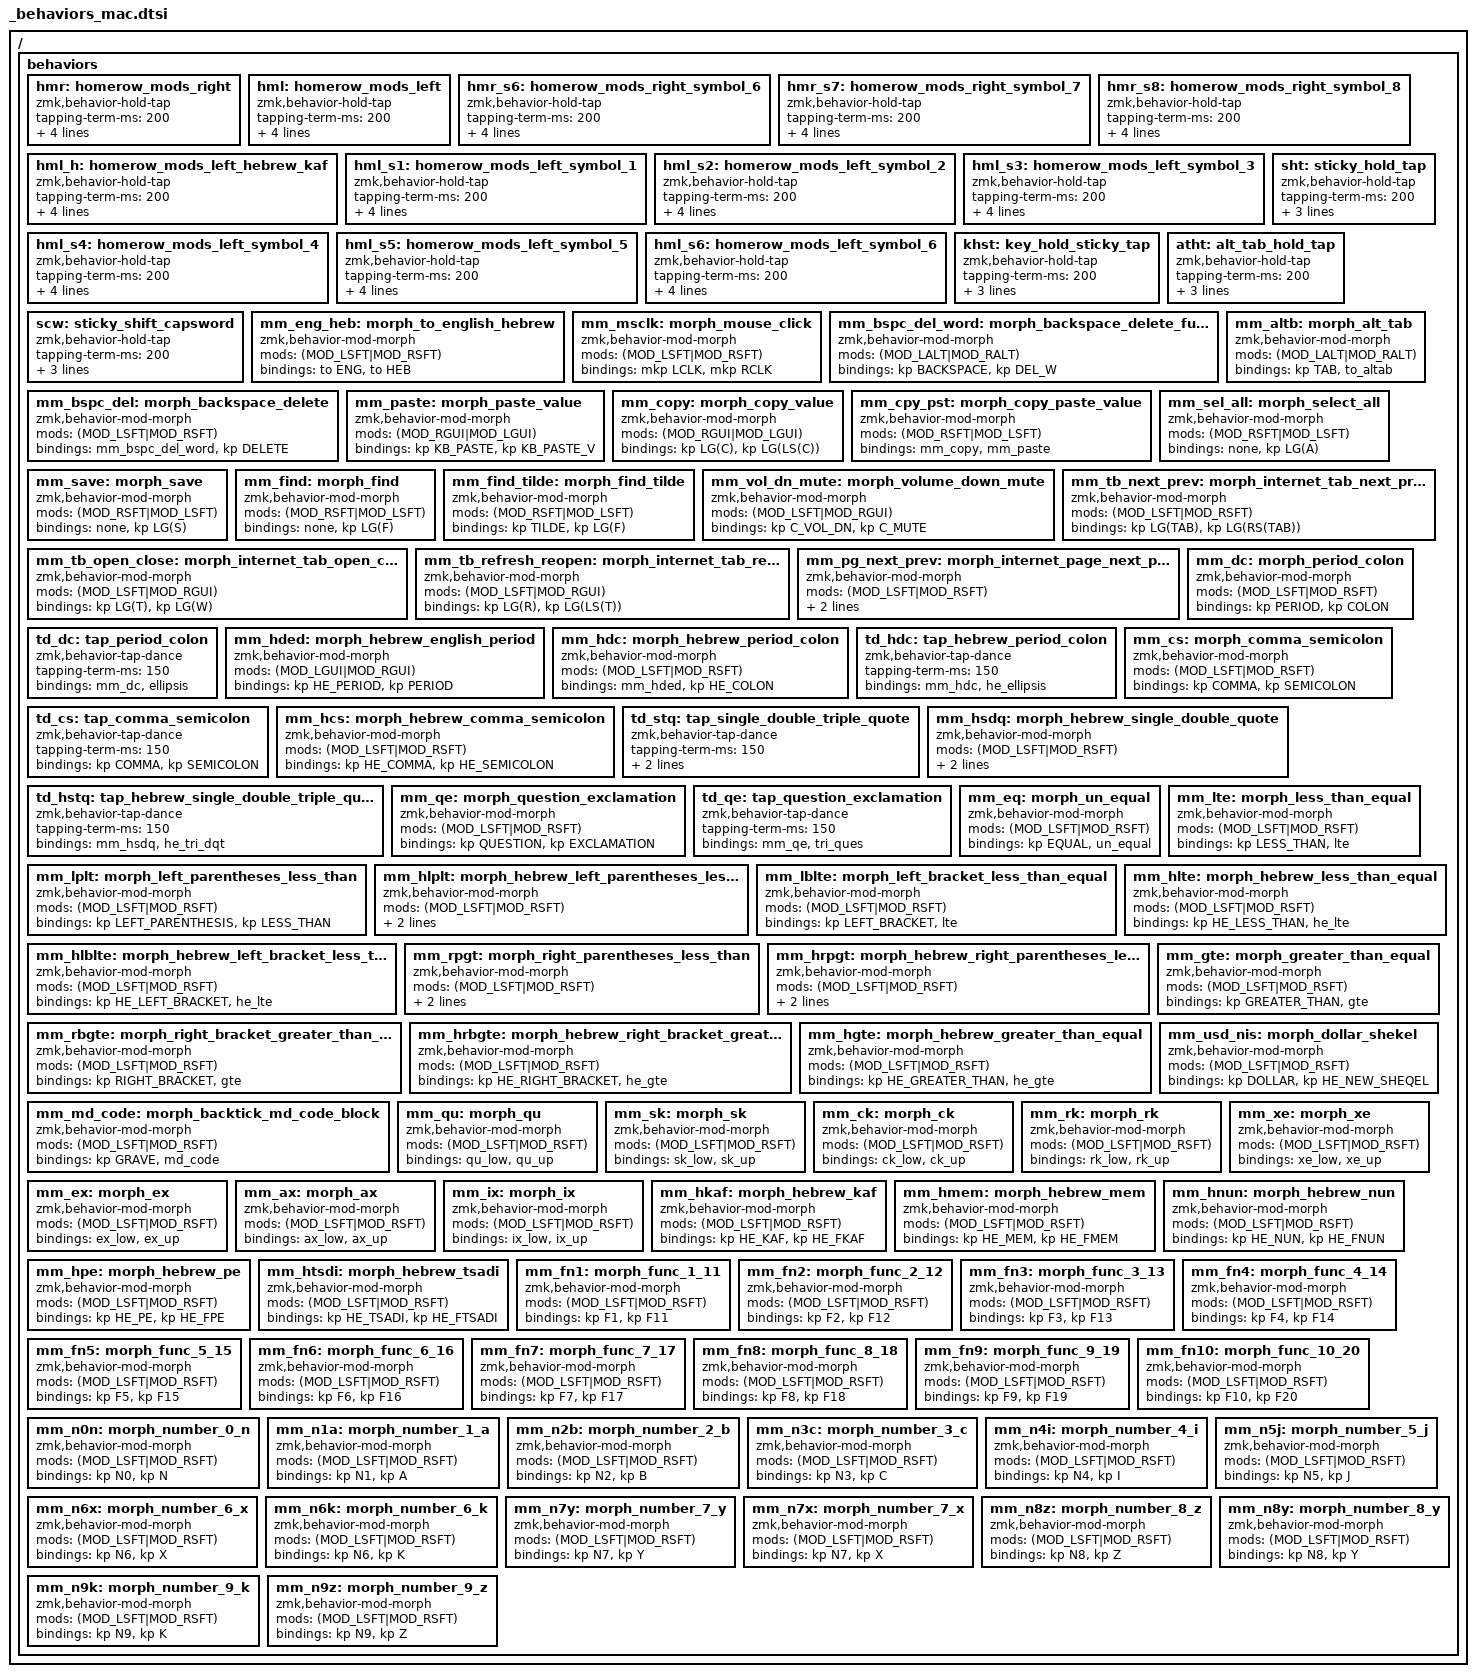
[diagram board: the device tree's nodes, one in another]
/ {
    behaviors {
        hmr: homerow_mods_right {
            compatible = "zmk,behavior-hold-tap";
            #binding-cells = <2>;
            tapping-term-ms = <200>;
            quick_tap_ms = <0>;
            flavor = "tap-preferred";
            bindings = <&kp>, <&kp>;
            hold-trigger-key-positions = <KEYS_L>;
        };

        hml: homerow_mods_left {
            compatible = "zmk,behavior-hold-tap";
            #binding-cells = <2>;
            tapping-term-ms = <200>;
            quick_tap_ms = <0>;
            flavor = "tap-preferred";
            bindings = <&kp>, <&kp>;
            hold-trigger-key-positions = <KEYS_R>;
        };

        hmr_s6: homerow_mods_right_symbol_6 {
            compatible = "zmk,behavior-hold-tap";
            #binding-cells = <2>;
            tapping-term-ms = <200>;
            quick_tap_ms = <0>;
            flavor = "tap-preferred";
            bindings = <&kp>, <&mm_n6x>;
            hold-trigger-key-positions = <KEYS_L>;
        };

        hmr_s7: homerow_mods_right_symbol_7 {
            compatible = "zmk,behavior-hold-tap";
            #binding-cells = <2>;
            tapping-term-ms = <200>;
            quick_tap_ms = <0>;
            flavor = "tap-preferred";
            bindings = <&kp>, <&mm_n7y>;
            hold-trigger-key-positions = <KEYS_L>;
        };

        hmr_s8: homerow_mods_right_symbol_8 {
            compatible = "zmk,behavior-hold-tap";
            #binding-cells = <2>;
            tapping-term-ms = <200>;
            quick_tap_ms = <0>;
            flavor = "tap-preferred";
            bindings = <&kp>, <&mm_n8z>;
            hold-trigger-key-positions = <KEYS_L>;
        };

        hml_h: homerow_mods_left_hebrew_kaf {
            compatible = "zmk,behavior-hold-tap";
            #binding-cells = <2>;
            tapping-term-ms = <200>;
            quick_tap_ms = <0>;
            flavor = "tap-preferred";
            bindings = <&kp>, <&mm_hkaf>;
            hold-trigger-key-positions = <KEYS_R>;
        };

        hml_s1: homerow_mods_left_symbol_1 {
            compatible = "zmk,behavior-hold-tap";
            #binding-cells = <2>;
            tapping-term-ms = <200>;
            quick_tap_ms = <0>;
            flavor = "tap-preferred";
            bindings = <&kp>, <&mm_n1a>;
            hold-trigger-key-positions = <KEYS_R>;
        };

        hml_s2: homerow_mods_left_symbol_2 {
            compatible = "zmk,behavior-hold-tap";
            #binding-cells = <2>;
            tapping-term-ms = <200>;
            quick_tap_ms = <0>;
            flavor = "tap-preferred";
            bindings = <&kp>, <&mm_n2b>;
            hold-trigger-key-positions = <KEYS_R>;
        };

        hml_s3: homerow_mods_left_symbol_3 {
            compatible = "zmk,behavior-hold-tap";
            #binding-cells = <2>;
            tapping-term-ms = <200>;
            quick_tap_ms = <0>;
            flavor = "tap-preferred";
            bindings = <&kp>, <&mm_n3c>;
            hold-trigger-key-positions = <KEYS_R>;
        };

        hml_s4: homerow_mods_left_symbol_4 {
            compatible = "zmk,behavior-hold-tap";
            #binding-cells = <2>;
            tapping-term-ms = <200>;
            quick_tap_ms = <0>;
            flavor = "tap-preferred";
            bindings = <&kp>, <&mm_n4i>;
            hold-trigger-key-positions = <KEYS_R>;
        };

        hml_s5: homerow_mods_left_symbol_5 {
            compatible = "zmk,behavior-hold-tap";
            #binding-cells = <2>;
            tapping-term-ms = <200>;
            quick_tap_ms = <0>;
            flavor = "tap-preferred";
            bindings = <&kp>, <&mm_n5j>;
            hold-trigger-key-positions = <KEYS_R>;
        };

        hml_s6: homerow_mods_left_symbol_6 {
            compatible = "zmk,behavior-hold-tap";
            #binding-cells = <2>;
            tapping-term-ms = <200>;
            quick_tap_ms = <0>;
            flavor = "tap-preferred";
            bindings = <&kp>, <&mm_n6k>;
            hold-trigger-key-positions = <KEYS_R>;
        };

        sht: sticky_hold_tap {
            compatible = "zmk,behavior-hold-tap";
            #binding-cells = <2>;
            tapping-term-ms = <200>;
            quick_tap_ms = <0>;
            flavor = "tap-preferred";
            bindings = <&sk>, <&kp>;
        };

        khst: key_hold_sticky_tap {
            compatible = "zmk,behavior-hold-tap";
            #binding-cells = <2>;
            tapping-term-ms = <200>;
            quick_tap_ms = <0>;
            flavor = "tap-preferred";
            bindings = <&kp>, <&sk>;
        };

        atht: alt_tab_hold_tap {
            compatible = "zmk,behavior-hold-tap";
            #binding-cells = <2>;
            tapping-term-ms = <200>;
            quick_tap_ms = <0>;
            flavor = "tap-preferred";
            bindings = <&to_altab>, <&kp>;
        };

        scw: sticky_shift_capsword {
            compatible = "zmk,behavior-hold-tap";
            #binding-cells = <2>;
            tapping-term-ms = <200>;
            quick_tap_ms = <0>;
            flavor = "tap-preferred";
            bindings = <&caps_word>, <&sk>;
        };

        // LAYER
        // To ENGLISH; Shifted: To Hebrew

        mm_eng_heb: morph_to_english_hebrew {
            compatible = "zmk,behavior-mod-morph";
            #binding-cells = <0>;
            mods = <(MOD_LSFT|MOD_RSFT)>;
            bindings = <&to ENG>, <&to HEB>;
        };

        // To KEYBOARD; Shifted: To MOUSE
        // To SYMBOL; Shifted: To KEYBOARD

        // mm_sys_fn: morph_to_system_function {
        //     compatible = "zmk,behavior-mod-morph";
        //     #binding-cells = <0>;
        //     mods = <(MOD_LSFT|MOD_RSFT)>;
        //     bindings = <&to SYS>, <&to FUN>;
        // };

        // To SYMBOL; Shifted: To MOUSE
        // MOD MORPHS
        // GENERAL

        mm_msclk: morph_mouse_click {
            compatible = "zmk,behavior-mod-morph";
            #binding-cells = <0>;
            mods = <(MOD_LSFT|MOD_RSFT)>;
            bindings = <&mkp LCLK>, <&mkp RCLK>;
        };

        mm_bspc_del_word: morph_backspace_delete_full_word {
            compatible = "zmk,behavior-mod-morph";
            #binding-cells = <0>;
            mods = <(MOD_LALT|MOD_RALT)>;
            bindings = <&kp BACKSPACE>, <&kp DEL_W>;
        };

        mm_bspc_del: morph_backspace_delete {
            compatible = "zmk,behavior-mod-morph";
            #binding-cells = <0>;
            mods = <(MOD_LSFT|MOD_RSFT)>;
            bindings = <&mm_bspc_del_word>, <&kp DELETE>;
        };

        mm_altb: morph_alt_tab {
            compatible = "zmk,behavior-mod-morph";
            #binding-cells = <0>;
            mods = <(MOD_LALT|MOD_RALT)>;
            bindings = <&kp TAB>, <&to_altab>;
        };

        // mm_paste: morph_paste_value {
        //     compatible = "zmk,behavior-mod-morph";
        //     #binding-cells = <0>;
        //     mods = <(MOD_RGUI|MOD_LGUI)>;
        //     bindings = <&kp LG(V)>, <&kp LG(LS(V))>;
        // };

        mm_paste: morph_paste_value {
            compatible = "zmk,behavior-mod-morph";
            #binding-cells = <0>;
            mods = <(MOD_RGUI|MOD_LGUI)>;
            bindings = <&kp KB_PASTE>, <&kp KB_PASTE_V>;
        };

        mm_copy: morph_copy_value {
            compatible = "zmk,behavior-mod-morph";
            #binding-cells = <0>;
            mods = <(MOD_RGUI|MOD_LGUI)>;
            bindings = <&kp LG(C)>, <&kp LG(LS(C))>;
        };

        mm_cpy_pst: morph_copy_paste_value {
            compatible = "zmk,behavior-mod-morph";
            #binding-cells = <0>;
            mods = <(MOD_RSFT|MOD_LSFT)>;
            bindings = <&mm_copy>, <&mm_paste>;
        };

        // mm_cpy_pst: morph_copy_paste {
        //     compatible = "zmk,behavior-mod-morph";
        //     #binding-cells = <0>;
        //     mods = <(MOD_RGUI|MOD_LGUI)>;
        //     bindings = <&kp LG(C)>, <&kp LG(V)>;
        // };

        mm_sel_all: morph_select_all {
            compatible = "zmk,behavior-mod-morph";
            #binding-cells = <0>;
            mods = <(MOD_RSFT|MOD_LSFT)>;
            bindings = <&none>, <&kp LG(A)>;
        };


        mm_save: morph_save {
            compatible = "zmk,behavior-mod-morph";
            #binding-cells = <0>;
            mods = <(MOD_RSFT|MOD_LSFT)>;
            bindings = <&none>, <&kp LG(S)>;
        };

        mm_find: morph_find {
            compatible = "zmk,behavior-mod-morph";
            #binding-cells = <0>;
            mods = <(MOD_RSFT|MOD_LSFT)>;
            bindings = <&none>, <&kp LG(F)>;
        };

        mm_find_tilde: morph_find_tilde {
            compatible = "zmk,behavior-mod-morph";
            #binding-cells = <0>;
            mods = <(MOD_RSFT|MOD_LSFT)>;
            bindings = <&kp TILDE>, <&kp LG(F)>;
        };

        mm_vol_dn_mute: morph_volume_down_mute {
            compatible = "zmk,behavior-mod-morph";
            #binding-cells = <0>;
            mods = <(MOD_LSFT|MOD_RGUI)>;
            bindings = <&kp C_VOL_DN>, <&kp C_MUTE>;
        };

        // INTERNET SHORTCUTS

        mm_tb_next_prev: morph_internet_tab_next_prev {
            compatible = "zmk,behavior-mod-morph";
            #binding-cells = <0>;
            mods = <(MOD_LSFT|MOD_RSFT)>;
            bindings = <&kp LG(TAB)>, <&kp LG(RS(TAB))>;
        };

        mm_tb_open_close: morph_internet_tab_open_close {
            compatible = "zmk,behavior-mod-morph";
            #binding-cells = <0>;
            mods = <(MOD_LSFT|MOD_RGUI)>;
            bindings = <&kp LG(T)>, <&kp LG(W)>;
        };

        mm_tb_refresh_reopen: morph_internet_tab_refresh_reop {
            compatible = "zmk,behavior-mod-morph";
            #binding-cells = <0>;
            mods = <(MOD_LSFT|MOD_RGUI)>;
            bindings = <&kp LG(R)>, <&kp LG(LS(T))>;
        };

        mm_pg_next_prev: morph_internet_page_next_prev {
            compatible = "zmk,behavior-mod-morph";
            #binding-cells = <0>;
            mods = <(MOD_LSFT|MOD_RSFT)>;
            bindings = <&kp LA(RIGHT_ARROW)>, <&kp LA(LEFT_ARROW)>;
        };

        // PUNCTUATION
        // Mod-Morph: Period "."; Colon ":"

        mm_dc: morph_period_colon {
            compatible = "zmk,behavior-mod-morph";
            #binding-cells = <0>;
            mods = <(MOD_LSFT|MOD_RSFT)>;
            bindings = <&kp PERIOD>, <&kp COLON>;
        };

        // Tap-Dance: 1) Mod-Morph Period-Colon; 2) Ellipsis "..."

        td_dc: tap_period_colon {
            compatible = "zmk,behavior-tap-dance";
            #binding-cells = <0>;
            tapping-term-ms = <150>;
            bindings = <&mm_dc>, <&ellipsis>;
        };

        // Mod-Morph: Period "."; Colon ":"

        mm_hded: morph_hebrew_english_period {
            compatible = "zmk,behavior-mod-morph";
            #binding-cells = <0>;
            mods = <(MOD_LGUI|MOD_RGUI)>;
            bindings = <&kp HE_PERIOD>, <&kp PERIOD>;
        };

        // Mod-Morph: Period "."; Colon ":"

        mm_hdc: morph_hebrew_period_colon {
            compatible = "zmk,behavior-mod-morph";
            #binding-cells = <0>;
            mods = <(MOD_LSFT|MOD_RSFT)>;
            bindings = <&mm_hded>, <&kp HE_COLON>;
        };

        // 1) Mod-Morph Period-Colon; 2) Ellipsis "..."

        td_hdc: tap_hebrew_period_colon {
            compatible = "zmk,behavior-tap-dance";
            #binding-cells = <0>;
            tapping-term-ms = <150>;
            bindings = <&mm_hdc>, <&he_ellipsis>;
        };

        // Mod-Morph: Comma ","; Semicolon ";"

        mm_cs: morph_comma_semicolon {
            compatible = "zmk,behavior-mod-morph";
            #binding-cells = <0>;
            mods = <(MOD_LSFT|MOD_RSFT)>;
            bindings = <&kp COMMA>, <&kp SEMICOLON>;
        };

        // Tap-Dance: 1) Comma ","; 2) Semicolon ";"

        td_cs: tap_comma_semicolon {
            compatible = "zmk,behavior-tap-dance";
            #binding-cells = <0>;
            tapping-term-ms = <150>;
            bindings = <&kp COMMA>, <&kp SEMICOLON>;
        };

        // Mod-Morph: Comma ","; Semicolon ";"

        mm_hcs: morph_hebrew_comma_semicolon {
            compatible = "zmk,behavior-mod-morph";
            #binding-cells = <0>;
            mods = <(MOD_LSFT|MOD_RSFT)>;
            bindings = <&kp HE_COMMA>, <&kp HE_SEMICOLON>;
        };

        // 1: Single quote "'"; 2: Double quote """; 3: Triple-double quote """""

        td_stq: tap_single_double_triple_quote {
            compatible = "zmk,behavior-tap-dance";
            #binding-cells = <0>;
            tapping-term-ms = <150>;
            bindings = <&kp SINGLE_QUOTE>, <&kp DOUBLE_QUOTES>, <&tri_dqt>;
        };

        // Mod-Morph: Single Quote "'"; Double Quote """

        mm_hsdq: morph_hebrew_single_double_quote {
            compatible = "zmk,behavior-mod-morph";
            #binding-cells = <0>;
            mods = <(MOD_LSFT|MOD_RSFT)>;
            bindings = <&kp HE_SINGLE_QUOTE>, <&kp HE_DOUBLE_QUOTES>;
        };

        // Tap-Dance: 1) Mod-Morph Single-Double Quote; 2) Triple-Double Quote """""

        td_hstq: tap_hebrew_single_double_triple_quote {
            compatible = "zmk,behavior-tap-dance";
            #binding-cells = <0>;
            tapping-term-ms = <150>;
            bindings = <&mm_hsdq>, <&he_tri_dqt>;
        };

        // Mod-Morph: Question "?"; Exclamation "!"

        mm_qe: morph_question_exclamation {
            compatible = "zmk,behavior-mod-morph";
            #binding-cells = <0>;
            mods = <(MOD_LSFT|MOD_RSFT)>;
            bindings = <&kp QUESTION>, <&kp EXCLAMATION>;
        };

        // Tap-Dance: 1) Mod-Morph Question-Exclamation; 2) Triple Question "???"

        td_qe: tap_question_exclamation {
            compatible = "zmk,behavior-tap-dance";
            #binding-cells = <0>;
            tapping-term-ms = <150>;
            bindings = <&mm_qe>, <&tri_ques>;
        };

        // MATH OPERATORS

        mm_eq: morph_un_equal {
            compatible = "zmk,behavior-mod-morph";
            #binding-cells = <0>;
            mods = <(MOD_LSFT|MOD_RSFT)>;
            bindings = <&kp EQUAL>, <&un_equal>;
        };

        mm_lplt: morph_left_parentheses_less_than {
            compatible = "zmk,behavior-mod-morph";
            #binding-cells = <0>;
            mods = <(MOD_LSFT|MOD_RSFT)>;
            bindings = <&kp LEFT_PARENTHESIS>, <&kp LESS_THAN>;
        };

        mm_hlplt: morph_hebrew_left_parentheses_less_than {
            compatible = "zmk,behavior-mod-morph";
            #binding-cells = <0>;
            mods = <(MOD_LSFT|MOD_RSFT)>;
            bindings = <&kp HE_LEFT_PARENTHESIS>, <&kp HE_LESS_THAN>;
        };

        mm_lblte: morph_left_bracket_less_than_equal {
            compatible = "zmk,behavior-mod-morph";
            #binding-cells = <0>;
            mods = <(MOD_LSFT|MOD_RSFT)>;
            bindings = <&kp LEFT_BRACKET>, <&lte>;
        };

        mm_hlblte: morph_hebrew_left_bracket_less_than_equal {
            compatible = "zmk,behavior-mod-morph";
            #binding-cells = <0>;
            mods = <(MOD_LSFT|MOD_RSFT)>;
            bindings = <&kp HE_LEFT_BRACKET>, <&he_lte>;
        };

        mm_lte: morph_less_than_equal {
            compatible = "zmk,behavior-mod-morph";
            #binding-cells = <0>;
            mods = <(MOD_LSFT|MOD_RSFT)>;
            bindings = <&kp LESS_THAN>, <&lte>;
        };

        mm_hlte: morph_hebrew_less_than_equal {
            compatible = "zmk,behavior-mod-morph";
            #binding-cells = <0>;
            mods = <(MOD_LSFT|MOD_RSFT)>;
            bindings = <&kp HE_LESS_THAN>, <&he_lte>;
        };

        mm_rpgt: morph_right_parentheses_less_than {
            compatible = "zmk,behavior-mod-morph";
            #binding-cells = <0>;
            mods = <(MOD_LSFT|MOD_RSFT)>;
            bindings = <&kp RIGHT_PARENTHESIS>, <&kp GREATER_THAN>;
        };

        mm_hrpgt: morph_hebrew_right_parentheses_less_than {
            compatible = "zmk,behavior-mod-morph";
            #binding-cells = <0>;
            mods = <(MOD_LSFT|MOD_RSFT)>;
            bindings = <&kp HE_RIGHT_PARENTHESIS>, <&kp HE_GREATER_THAN>;
        };

        mm_rbgte: morph_right_bracket_greater_than_equal {
            compatible = "zmk,behavior-mod-morph";
            #binding-cells = <0>;
            mods = <(MOD_LSFT|MOD_RSFT)>;
            bindings = <&kp RIGHT_BRACKET>, <&gte>;
        };

        mm_hrbgte: morph_hebrew_right_bracket_greater_than_equal {
            compatible = "zmk,behavior-mod-morph";
            #binding-cells = <0>;
            mods = <(MOD_LSFT|MOD_RSFT)>;
            bindings = <&kp HE_RIGHT_BRACKET>, <&he_gte>;
        };

        mm_gte: morph_greater_than_equal {
            compatible = "zmk,behavior-mod-morph";
            #binding-cells = <0>;
            mods = <(MOD_LSFT|MOD_RSFT)>;
            bindings = <&kp GREATER_THAN>, <&gte>;
        };

        mm_hgte: morph_hebrew_greater_than_equal {
            compatible = "zmk,behavior-mod-morph";
            #binding-cells = <0>;
            mods = <(MOD_LSFT|MOD_RSFT)>;
            bindings = <&kp HE_GREATER_THAN>, <&he_gte>;
        };

        mm_md_code: morph_backtick_md_code_block {
            compatible = "zmk,behavior-mod-morph";
            #binding-cells = <0>;
            mods = <(MOD_LSFT|MOD_RSFT)>;
            bindings = <&kp GRAVE>, <&md_code>;
        };

        // CHARACTERS
        // Mod-Morph: $; ₪
        mm_usd_nis: morph_dollar_shekel {
            compatible = "zmk,behavior-mod-morph";
            #binding-cells = <0>;
            mods = <(MOD_LSFT|MOD_RSFT)>;
            bindings = <&kp DOLLAR>, <&kp HE_NEW_SHEQEL>;
        };

        // LETTERS
        // Mod-Morph: qu; Qu

        mm_qu: morph_qu {
            compatible = "zmk,behavior-mod-morph";
            #binding-cells = <0>;
            mods = <(MOD_LSFT|MOD_RSFT)>;
            bindings = <&qu_low>, <&qu_up>;
        };

        // Mod-Morph: sk; Sk

        mm_sk: morph_sk {
            compatible = "zmk,behavior-mod-morph";
            #binding-cells = <0>;
            mods = <(MOD_LSFT|MOD_RSFT)>;
            bindings = <&sk_low>, <&sk_up>;
        };

        // Mod-Morph: ck; Ck

        mm_ck: morph_ck {
            compatible = "zmk,behavior-mod-morph";
            #binding-cells = <0>;
            mods = <(MOD_LSFT|MOD_RSFT)>;
            bindings = <&ck_low>, <&ck_up>;
        };

        // Mod-Morph: rk; Rk

        mm_rk: morph_rk {
            compatible = "zmk,behavior-mod-morph";
            #binding-cells = <0>;
            mods = <(MOD_LSFT|MOD_RSFT)>;
            bindings = <&rk_low>, <&rk_up>;
        };

        // Mod-Morph: xe; Xe

        mm_xe: morph_xe {
            compatible = "zmk,behavior-mod-morph";
            #binding-cells = <0>;
            mods = <(MOD_LSFT|MOD_RSFT)>;
            bindings = <&xe_low>, <&xe_up>;
        };

        // Mod-Morph: ex; Ex

        mm_ex: morph_ex {
            compatible = "zmk,behavior-mod-morph";
            #binding-cells = <0>;
            mods = <(MOD_LSFT|MOD_RSFT)>;
            bindings = <&ex_low>, <&ex_up>;
        };

        // Mod-Morph: ax; Ax

        mm_ax: morph_ax {
            compatible = "zmk,behavior-mod-morph";
            #binding-cells = <0>;
            mods = <(MOD_LSFT|MOD_RSFT)>;
            bindings = <&ax_low>, <&ax_up>;
        };

        // Mod-Morph: ix; Ix

        mm_ix: morph_ix {
            compatible = "zmk,behavior-mod-morph";
            #binding-cells = <0>;
            mods = <(MOD_LSFT|MOD_RSFT)>;
            bindings = <&ix_low>, <&ix_up>;
        };

        // Mod-Morph: Kaf כ; Final Kaf ך

        mm_hkaf: morph_hebrew_kaf {
            compatible = "zmk,behavior-mod-morph";
            #binding-cells = <0>;
            mods = <(MOD_LSFT|MOD_RSFT)>;
            bindings = <&kp HE_KAF>, <&kp HE_FKAF>;
        };

        // Mod-Morph: Mem מ; Final Mem ם

        mm_hmem: morph_hebrew_mem {
            compatible = "zmk,behavior-mod-morph";
            #binding-cells = <0>;
            mods = <(MOD_LSFT|MOD_RSFT)>;
            bindings = <&kp HE_MEM>, <&kp HE_FMEM>;
        };

        // Mod-Morph: Nun נ; Final Nun ן

        mm_hnun: morph_hebrew_nun {
            compatible = "zmk,behavior-mod-morph";
            #binding-cells = <0>;
            mods = <(MOD_LSFT|MOD_RSFT)>;
            bindings = <&kp HE_NUN>, <&kp HE_FNUN>;
        };

        // Mod-Morph: Peh פ; Final Peh ף

        mm_hpe: morph_hebrew_pe {
            compatible = "zmk,behavior-mod-morph";
            #binding-cells = <0>;
            mods = <(MOD_LSFT|MOD_RSFT)>;
            bindings = <&kp HE_PE>, <&kp HE_FPE>;
        };

        // Mod-Morph: Tsadi צ; Final Tsadi ץ

        mm_htsdi: morph_hebrew_tsadi {
            compatible = "zmk,behavior-mod-morph";
            #binding-cells = <0>;
            mods = <(MOD_LSFT|MOD_RSFT)>;
            bindings = <&kp HE_TSADI>, <&kp HE_FTSADI>;
        };

        // FUNCTION PLUS TEN

        mm_fn1: morph_func_1_11 {
            compatible = "zmk,behavior-mod-morph";
            #binding-cells = <0>;
            mods = <(MOD_LSFT|MOD_RSFT)>;
            bindings = <&kp F1>, <&kp F11>;
        };

        mm_fn2: morph_func_2_12 {
            compatible = "zmk,behavior-mod-morph";
            #binding-cells = <0>;
            mods = <(MOD_LSFT|MOD_RSFT)>;
            bindings = <&kp F2>, <&kp F12>;
        };

        mm_fn3: morph_func_3_13 {
            compatible = "zmk,behavior-mod-morph";
            #binding-cells = <0>;
            mods = <(MOD_LSFT|MOD_RSFT)>;
            bindings = <&kp F3>, <&kp F13>;
        };

        mm_fn4: morph_func_4_14 {
            compatible = "zmk,behavior-mod-morph";
            #binding-cells = <0>;
            mods = <(MOD_LSFT|MOD_RSFT)>;
            bindings = <&kp F4>, <&kp F14>;
        };

        mm_fn5: morph_func_5_15 {
            compatible = "zmk,behavior-mod-morph";
            #binding-cells = <0>;
            mods = <(MOD_LSFT|MOD_RSFT)>;
            bindings = <&kp F5>, <&kp F15>;
        };

        mm_fn6: morph_func_6_16 {
            compatible = "zmk,behavior-mod-morph";
            #binding-cells = <0>;
            mods = <(MOD_LSFT|MOD_RSFT)>;
            bindings = <&kp F6>, <&kp F16>;
        };

        mm_fn7: morph_func_7_17 {
            compatible = "zmk,behavior-mod-morph";
            #binding-cells = <0>;
            mods = <(MOD_LSFT|MOD_RSFT)>;
            bindings = <&kp F7>, <&kp F17>;
        };

        mm_fn8: morph_func_8_18 {
            compatible = "zmk,behavior-mod-morph";
            #binding-cells = <0>;
            mods = <(MOD_LSFT|MOD_RSFT)>;
            bindings = <&kp F8>, <&kp F18>;
        };

        mm_fn9: morph_func_9_19 {
            compatible = "zmk,behavior-mod-morph";
            #binding-cells = <0>;
            mods = <(MOD_LSFT|MOD_RSFT)>;
            bindings = <&kp F9>, <&kp F19>;
        };

        mm_fn10: morph_func_10_20 {
            compatible = "zmk,behavior-mod-morph";
            #binding-cells = <0>;
            mods = <(MOD_LSFT|MOD_RSFT)>;
            bindings = <&kp F10>, <&kp F20>;
        };

        // NUMBER AND COMMON MATH VARIABLES

        mm_n0n: morph_number_0_n {
            compatible = "zmk,behavior-mod-morph";
            #binding-cells = <0>;
            mods = <(MOD_LSFT|MOD_RSFT)>;
            bindings = <&kp N0>, <&kp N>;
        };

        mm_n1a: morph_number_1_a {
            compatible = "zmk,behavior-mod-morph";
            #binding-cells = <0>;
            mods = <(MOD_LSFT|MOD_RSFT)>;
            bindings = <&kp N1>, <&kp A>;
        };

        mm_n2b: morph_number_2_b {
            compatible = "zmk,behavior-mod-morph";
            #binding-cells = <0>;
            mods = <(MOD_LSFT|MOD_RSFT)>;
            bindings = <&kp N2>, <&kp B>;
        };

        mm_n3c: morph_number_3_c {
            compatible = "zmk,behavior-mod-morph";
            #binding-cells = <0>;
            mods = <(MOD_LSFT|MOD_RSFT)>;
            bindings = <&kp N3>, <&kp C>;
        };

        mm_n4i: morph_number_4_i {
            compatible = "zmk,behavior-mod-morph";
            #binding-cells = <0>;
            mods = <(MOD_LSFT|MOD_RSFT)>;
            bindings = <&kp N4>, <&kp I>;
        };

        mm_n5j: morph_number_5_j {
            compatible = "zmk,behavior-mod-morph";
            #binding-cells = <0>;
            mods = <(MOD_LSFT|MOD_RSFT)>;
            bindings = <&kp N5>, <&kp J>;
        };

        mm_n6x: morph_number_6_x {
            compatible = "zmk,behavior-mod-morph";
            #binding-cells = <0>;
            mods = <(MOD_LSFT|MOD_RSFT)>;
            bindings = <&kp N6>, <&kp X>;
        };

        mm_n6k: morph_number_6_k {
            compatible = "zmk,behavior-mod-morph";
            #binding-cells = <0>;
            mods = <(MOD_LSFT|MOD_RSFT)>;
            bindings = <&kp N6>, <&kp K>;
        };

        mm_n7y: morph_number_7_y {
            compatible = "zmk,behavior-mod-morph";
            #binding-cells = <0>;
            mods = <(MOD_LSFT|MOD_RSFT)>;
            bindings = <&kp N7>, <&kp Y>;
        };

        mm_n7x: morph_number_7_x {
            compatible = "zmk,behavior-mod-morph";
            #binding-cells = <0>;
            mods = <(MOD_LSFT|MOD_RSFT)>;
            bindings = <&kp N7>, <&kp X>;
        };

        mm_n8z: morph_number_8_z {
            compatible = "zmk,behavior-mod-morph";
            #binding-cells = <0>;
            mods = <(MOD_LSFT|MOD_RSFT)>;
            bindings = <&kp N8>, <&kp Z>;
        };

        mm_n8y: morph_number_8_y {
            compatible = "zmk,behavior-mod-morph";
            #binding-cells = <0>;
            mods = <(MOD_LSFT|MOD_RSFT)>;
            bindings = <&kp N8>, <&kp Y>;
        };

        mm_n9k: morph_number_9_k {
            compatible = "zmk,behavior-mod-morph";
            #binding-cells = <0>;
            mods = <(MOD_LSFT|MOD_RSFT)>;
            bindings = <&kp N9>, <&kp K>;
        };

        mm_n9z: morph_number_9_z {
            compatible = "zmk,behavior-mod-morph";
            #binding-cells = <0>;
            mods = <(MOD_LSFT|MOD_RSFT)>;
            bindings = <&kp N9>, <&kp Z>;
        };
    };
};
